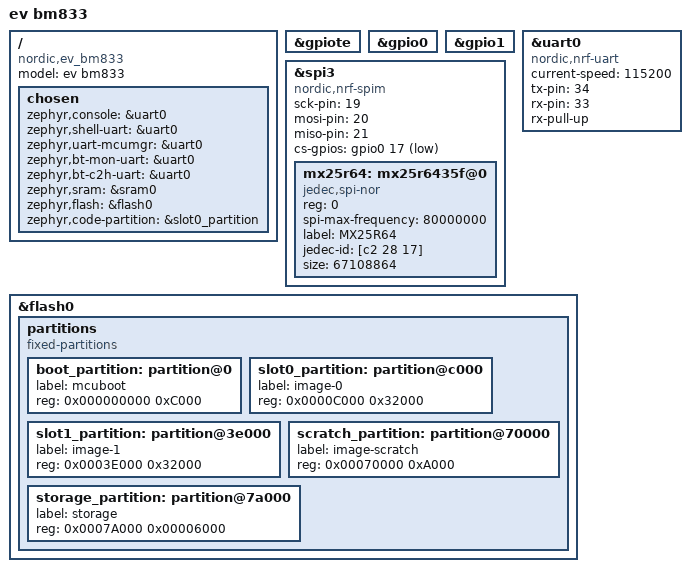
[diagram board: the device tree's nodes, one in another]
/*
 * Copyright (c) 2022 traxon technologies
 */

/dts-v1/;
#include <nordic/nrf52833_qiaa.dtsi>

/ {
    model = "ev bm833";
    compatible = "nordic,ev_bm833";

    chosen {
        zephyr,console = &uart0;
        zephyr,shell-uart = &uart0;
        zephyr,uart-mcumgr = &uart0;
        zephyr,bt-mon-uart = &uart0;
        zephyr,bt-c2h-uart = &uart0;
        zephyr,sram = &sram0;
        zephyr,flash = &flash0;
        zephyr,code-partition = &slot0_partition;
    };
};

&gpiote {
    status = "okay";
};

&gpio0 {
    status = "okay";
};

&gpio1 {
    status = "okay";
};

&uart0 {
    compatible = "nordic,nrf-uart";
    status = "okay";
    current-speed = <115200>;
    tx-pin = <34>;
    rx-pin = <33>;
    rx-pull-up;
};

&spi3 {
    compatible = "nordic,nrf-spim";
    status = "okay";
    sck-pin = <19>;
    mosi-pin = <20>;
    miso-pin = <21>;
    cs-gpios = <&gpio0 17 GPIO_ACTIVE_LOW>;
    mx25r64: mx25r6435f@0 {
        compatible = "jedec,spi-nor";
        reg = <0>;
        spi-max-frequency = <80000000>;
        label = "MX25R64";
        jedec-id = [c2 28 17];
        size = <67108864>;
    };
};

&flash0 {
    partitions {
        compatible = "fixed-partitions";
        #address-cells = <1>;
        #size-cells = <1>;

        boot_partition: partition@0 {
            label = "mcuboot";
            reg = <0x000000000 0xC000>;
        };
        slot0_partition: partition@c000 {
            label = "image-0";
            reg = <0x0000C000 0x32000>;
        };
        slot1_partition: partition@3e000 {
            label = "image-1";
            reg = <0x0003E000 0x32000>;
        };
        scratch_partition: partition@70000 {
            label = "image-scratch";
            reg = <0x00070000 0xA000>;
        };
        storage_partition: partition@7a000 {
            label = "storage";
            reg = <0x0007A000 0x00006000>;
        };
    };
};
